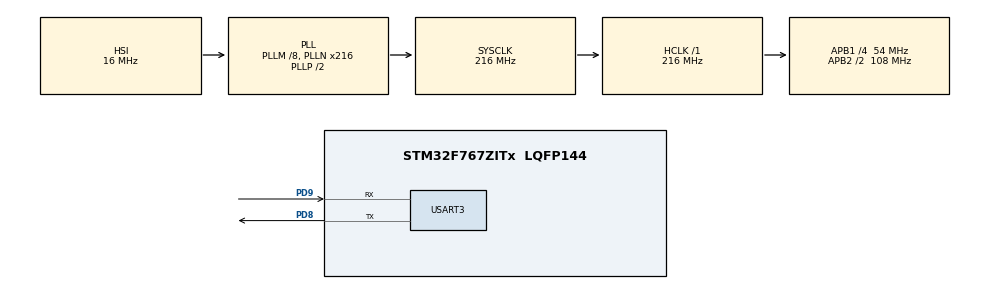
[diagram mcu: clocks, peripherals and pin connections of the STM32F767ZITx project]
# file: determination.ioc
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CORTEX_M7.CPU_DCache=Enabled
CORTEX_M7.CPU_ICache=Enabled
Mcu.Family=STM32F7
Mcu.Name=STM32F767ZITx
Mcu.Package=LQFP144
NVIC.PriorityGroup=NVIC_PRIORITYGROUP_4
PD8.Mode=Asynchronous
PD8.Signal=USART3_TX
PD9.Mode=Asynchronous
PD9.Signal=USART3_RX
ProjectManager.HeapSize=0x2000
ProjectManager.StackSize=0x800
ProjectManager.TargetToolchain=STM32CubeIDE
RCC.AHBFreq_Value=216000000
RCC.APB1CLKDivider=RCC_HCLK_DIV4
RCC.APB1Freq_Value=54000000
RCC.APB1TimFreq_Value=108000000
RCC.APB2CLKDivider=RCC_HCLK_DIV2
RCC.APB2Freq_Value=108000000
RCC.APB2TimFreq_Value=216000000
RCC.CortexFreq_Value=216000000
RCC.HCLKFreq_Value=216000000
RCC.HSE_VALUE=25000000
RCC.HSI_VALUE=16000000
RCC.LSE_VALUE=32768
RCC.PLLM=8
RCC.PLLN=216
RCC.SYSCLKFreq_VALUE=216000000
RCC.SYSCLKSource=RCC_SYSCLKSOURCE_PLLCLK
RCC.USBFreq_Value=216000000
RCC.VCOOutputFreq_Value=432000000
STMicroelectronics.X-CUBE-AI.5.0.0.ActivationBufferSizeList=192
STMicroelectronics.X-CUBE-AI.5.0.0.ApplicationCcArtificialOoIntelligenceJjApplication=Validation
STMicroelectronics.X-CUBE-AI.5.0.0.BSP.number=1
STMicroelectronics.X-CUBE-AI.5.0.0.HeapSize=0x2000
STMicroelectronics.X-CUBE-AI.5.0.0.InternalRamActivationBufferMaxSize=AI_NETWORK_1582985458502_DATA_ACTIVATIONS_SIZE
STMicroelectronics.X-CUBE-AI.5.0.0.LatestDirectoryUsed-8477a0a59f1d5497c4aba0388fbc2898b4da474dbaf260314755d35275862865=C\:\\Users\\ma26l\\Desktop\\IUT\\IA-Embarquee\\pyfiles\\voltGraphLearning
STMicroelectronics.X-CUBE-AI.5.0.0.MaximumNumberOfInputLayer=1
STMicroelectronics.X-CUBE-AI.5.0.0.MaximumNumberOfOutputLayer=1
STMicroelectronics.X-CUBE-AI.5.0.0.MaximumSizeOfInputLayer=400
STMicroelectronics.X-CUBE-AI.5.0.0.MaximumSizeOfOutputLayer=12
STMicroelectronics.X-CUBE-AI.5.0.0.ModelActualCompression-8477a0a59f1d5497c4aba0388fbc2898b4da474dbaf260314755d35275862865=0.0
STMicroelectronics.X-CUBE-AI.5.0.0.ModelCompression-8477a0a59f1d5497c4aba0388fbc2898b4da474dbaf260314755d35275862865=8
STMicroelectronics.X-CUBE-AI.5.0.0.ModelFlashOccupation-8477a0a59f1d5497c4aba0388fbc2898b4da474dbaf260314755d35275862865=2108
STMicroelectronics.X-CUBE-AI.5.0.0.ModelHashList=8477a0a59f1d5497c4aba0388fbc2898b4da474dbaf260314755d35275862865
STMicroelectronics.X-CUBE-AI.5.0.0.ModelKind-8477a0a59f1d5497c4aba0388fbc2898b4da474dbaf260314755d35275862865=TFLITE
STMicroelectronics.X-CUBE-AI.5.0.0.ModelMacc-8477a0a59f1d5497c4aba0388fbc2898b4da474dbaf260314755d35275862865=3126
STMicroelectronics.X-CUBE-AI.5.0.0.ModelNameList=network_1582985458502
STMicroelectronics.X-CUBE-AI.5.0.0.ModelRamOccupation-8477a0a59f1d5497c4aba0388fbc2898b4da474dbaf260314755d35275862865=192
STMicroelectronics.X-CUBE-AI.5.0.0.ModelStructureFile-8477a0a59f1d5497c4aba0388fbc2898b4da474dbaf260314755d35275862865=C\:\\Users\\ma26l\\Desktop\\IUT\\IA-Embarquee\\pyfiles\\voltGraphLearning\\reseau2.tflite
STMicroelectronics.X-CUBE-AI.5.0.0.ModelType-8477a0a59f1d5497c4aba0388fbc2898b4da474dbaf260314755d35275862865=Saved model
STMicroelectronics.X-CUBE-AI.5.0.0.NNModelInformation_AchievedCompression-8477a0a59f1d5497c4aba0388fbc2898b4da474dbaf260314755d35275862865=0.0
STMicroelectronics.X-CUBE-AI.5.0.0.NNModelInformation_CompressionFactor-8477a0a59f1d5497c4aba0388fbc2898b4da474dbaf260314755d35275862865=-0.829945143594708
STMicroelectronics.X-CUBE-AI.5.0.0.NNModelInformation_EvaluationStatus-8477a0a59f1d5497c4aba0388fbc2898b4da474dbaf260314755d35275862865=NOT EVALUATED
STMicroelectronics.X-CUBE-AI.5.0.0.NNModelInformation_HeapSizeNeeded-8477a0a59f1d5497c4aba0388fbc2898b4da474dbaf260314755d35275862865=2048
STMicroelectronics.X-CUBE-AI.5.0.0.NNModelInformation_ModelInSizeByName-8477a0a59f1d5497c4aba0388fbc2898b4da474dbaf260314755d35275862865={input_0\=400}
STMicroelectronics.X-CUBE-AI.5.0.0.NNModelInformation_ModelMacc-8477a0a59f1d5497c4aba0388fbc2898b4da474dbaf260314755d35275862865=3126
STMicroelectronics.X-CUBE-AI.5.0.0.NNModelInformation_ModelName-8477a0a59f1d5497c4aba0388fbc2898b4da474dbaf260314755d35275862865=network_1582985458502
STMicroelectronics.X-CUBE-AI.5.0.0.NNModelInformation_ModelOutSizeByName-8477a0a59f1d5497c4aba0388fbc2898b4da474dbaf260314755d35275862865={nl_3\=12}
STMicroelectronics.X-CUBE-AI.5.0.0.NNModelInformation_ModelRam-8477a0a59f1d5497c4aba0388fbc2898b4da474dbaf260314755d35275862865=192
STMicroelectronics.X-CUBE-AI.5.0.0.NNModelInformation_ModelRom-8477a0a59f1d5497c4aba0388fbc2898b4da474dbaf260314755d35275862865=2108
STMicroelectronics.X-CUBE-AI.5.0.0.NNModelInformation_ModelSize-8477a0a59f1d5497c4aba0388fbc2898b4da474dbaf260314755d35275862865=12396
STMicroelectronics.X-CUBE-AI.5.0.0.NNModelInformation_NbOfParameters-8477a0a59f1d5497c4aba0388fbc2898b4da474dbaf260314755d35275862865=3099
STMicroelectronics.X-CUBE-AI.5.0.0.StackSize=0x800
STMicroelectronics.X-CUBE-AI.5.0.0.WorkingBufferStartAddrList=0xFFFFFFFF
STMicroelectronics.X-CUBE-AI.5.0.0.XAaCUBEAaAICcArtificialOoIntelligenceJjCore=true
STMicroelectronics.X-CUBE-AI.5.0.00.BSP.STBoard=false
STMicroelectronics.X-CUBE-AI.5.0.00.BSP.api=Unknown
STMicroelectronics.X-CUBE-AI.5.0.00.BSP.condition=\!SEMArtificialOoIntelligenceJjApplicationJjApplicationTemplate
STMicroelectronics.X-CUBE-AI.5.0.00.BSP.i2caddr=0
STMicroelectronics.X-CUBE-AI.5.0.00.BSP.instance=USART3
STMicroelectronics.X-CUBE-AI.5.0.00.BSP.ip=USART
STMicroelectronics.X-CUBE-AI.5.0.00.BSP.mode=Asynchronous
STMicroelectronics.X-CUBE-AI.5.0.00.BSP.name=COM Port
STMicroelectronics.X-CUBE-AI.5.0.00.BSP.solution=USART3
USART3.VirtualMode-Asynchronous=VM_ASYNC
VP_CRC_VS_CRC.Mode=CRC_Activate
VP_STMicroelectronics.X-CUBE-AI_VS_ArtificialOoIntelligenceJjApplication_5.0.0.Mode=ArtificialOoIntelligenceJjApplication
VP_STMicroelectronics.X-CUBE-AI_VS_ArtificialOoIntelligenceJjXAaCUBEAaAI_5.0.0.Mode=ArtificialOoIntelligenceJjXAaCUBEAaAI
board=custom

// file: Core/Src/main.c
/* USER CODE BEGIN Header */
/**
  ******************************************************************************
  * @file           : main.c
  * @brief          : Main program body
  ******************************************************************************
  * @attention
  *
  * <h2><center>&copy; Copyright (c) 2020 STMicroelectronics.
  * All rights reserved.</center></h2>
  *
  * This software component is licensed by ST under BSD 3-Clause license,
  * the "License"; You may not use this file except in compliance with the
  * License. You may obtain a copy of the License at:
  *                        opensource.org/licenses/BSD-3-Clause
  *
  ******************************************************************************
  */
/* USER CODE END Header */

#include "main.h"
#include "app_x-cube-ai.h"

/* USER CODE BEGIN Includes */
#include <stdio.h>
/* USER CODE END Includes */

CRC_HandleTypeDef hcrc;

UART_HandleTypeDef huart3;

void SystemClock_Config(void);
static void MX_GPIO_Init(void);
static void MX_CRC_Init(void);
void MX_USART3_UART_Init(void);

int main(void)
{

  /* Enable I-Cache---------------------------------------------------------*/
  SCB_EnableICache();

  /* Enable D-Cache---------------------------------------------------------*/
  SCB_EnableDCache();

  /* MCU Configuration--------------------------------------------------------*/

  /* Reset of all peripherals, Initializes the Flash interface and the Systick. */
  HAL_Init();

  /* Configure the system clock */
  SystemClock_Config();

  /* Initialize all configured peripherals */
  MX_GPIO_Init();
  MX_CRC_Init();
  MX_X_CUBE_AI_Init();
  /* USER CODE BEGIN 2 */

  MX_USART3_UART_Init();
  printf("test");
  /* USER CODE END 2 */

  /* Infinite loop */
  while (1){
	MX_X_CUBE_AI_Process();

  }
}

void SystemClock_Config(void) {
  RCC_OscInitTypeDef RCC_OscInitStruct = {0};
  RCC_ClkInitTypeDef RCC_ClkInitStruct = {0};
  RCC_PeriphCLKInitTypeDef PeriphClkInitStruct = {0};

  /** Configure the main internal regulator output voltage
  */
  __HAL_RCC_PWR_CLK_ENABLE();
  __HAL_PWR_VOLTAGESCALING_CONFIG(PWR_REGULATOR_VOLTAGE_SCALE1);
  /** Initializes the CPU, AHB and APB busses clocks
  */
  RCC_OscInitStruct.OscillatorType = RCC_OSCILLATORTYPE_HSI;
  RCC_OscInitStruct.HSIState = RCC_HSI_ON;
  RCC_OscInitStruct.HSICalibrationValue = RCC_HSICALIBRATION_DEFAULT;
  RCC_OscInitStruct.PLL.PLLState = RCC_PLL_ON;
  RCC_OscInitStruct.PLL.PLLSource = RCC_PLLSOURCE_HSI;
  RCC_OscInitStruct.PLL.PLLM = 8;
  RCC_OscInitStruct.PLL.PLLN = 216;
  RCC_OscInitStruct.PLL.PLLP = RCC_PLLP_DIV2;
  RCC_OscInitStruct.PLL.PLLQ = 2;
  if (HAL_RCC_OscConfig(&RCC_OscInitStruct) != HAL_OK)
  {
    Error_Handler();
  }
  /** Activate the Over-Drive mode
  */
  if (HAL_PWREx_EnableOverDrive() != HAL_OK)
  {
    Error_Handler();
  }
  /** Initializes the CPU, AHB and APB busses clocks
  */
  RCC_ClkInitStruct.ClockType = RCC_CLOCKTYPE_HCLK|RCC_CLOCKTYPE_SYSCLK
                              |RCC_CLOCKTYPE_PCLK1|RCC_CLOCKTYPE_PCLK2;
  RCC_ClkInitStruct.SYSCLKSource = RCC_SYSCLKSOURCE_PLLCLK;
  RCC_ClkInitStruct.AHBCLKDivider = RCC_SYSCLK_DIV1;
  RCC_ClkInitStruct.APB1CLKDivider = RCC_HCLK_DIV4;
  RCC_ClkInitStruct.APB2CLKDivider = RCC_HCLK_DIV2;

  if (HAL_RCC_ClockConfig(&RCC_ClkInitStruct, FLASH_LATENCY_7) != HAL_OK)
  {
    Error_Handler();
  }
  PeriphClkInitStruct.PeriphClockSelection = RCC_PERIPHCLK_USART3;
  PeriphClkInitStruct.Usart3ClockSelection = RCC_USART3CLKSOURCE_PCLK1;
  if (HAL_RCCEx_PeriphCLKConfig(&PeriphClkInitStruct) != HAL_OK)
  {
    Error_Handler();
  }
}

static void MX_CRC_Init(void)
{

  hcrc.Instance = CRC;
  hcrc.Init.DefaultPolynomialUse = DEFAULT_POLYNOMIAL_ENABLE;
  hcrc.Init.DefaultInitValueUse = DEFAULT_INIT_VALUE_ENABLE;
  hcrc.Init.InputDataInversionMode = CRC_INPUTDATA_INVERSION_NONE;
  hcrc.Init.OutputDataInversionMode = CRC_OUTPUTDATA_INVERSION_DISABLE;
  hcrc.InputDataFormat = CRC_INPUTDATA_FORMAT_BYTES;
  if (HAL_CRC_Init(&hcrc) != HAL_OK)
  {
    Error_Handler();
  }

}

void MX_USART3_UART_Init(void)
{

  huart3.Instance = USART3;
  huart3.Init.BaudRate = 115200;
  huart3.Init.WordLength = UART_WORDLENGTH_8B;
  huart3.Init.StopBits = UART_STOPBITS_1;
  huart3.Init.Parity = UART_PARITY_NONE;
  huart3.Init.Mode = UART_MODE_TX_RX;
  huart3.Init.HwFlowCtl = UART_HWCONTROL_NONE;
  huart3.Init.OverSampling = UART_OVERSAMPLING_16;
  huart3.Init.OneBitSampling = UART_ONE_BIT_SAMPLE_DISABLE;
  huart3.AdvancedInit.AdvFeatureInit = UART_ADVFEATURE_NO_INIT;
  if (HAL_UART_Init(&huart3) != HAL_OK)
  {
    Error_Handler();
  }

}

static void MX_GPIO_Init(void)
{

  /* GPIO Ports Clock Enable */
  __HAL_RCC_GPIOD_CLK_ENABLE();

}

void Error_Handler(void)
{
}

/************************ (C) COPYRIGHT STMicroelectronics *****END OF FILE****/
